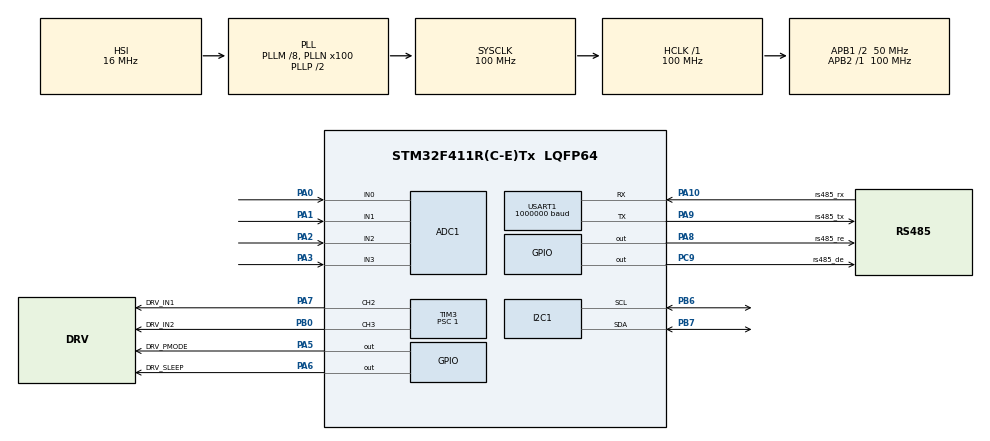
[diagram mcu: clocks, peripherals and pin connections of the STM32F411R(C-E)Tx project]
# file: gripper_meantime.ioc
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ADC1.Channel-0\#ChannelRegularConversion=ADC_CHANNEL_0
ADC1.Channel-1\#ChannelRegularConversion=ADC_CHANNEL_1
ADC1.Channel-2\#ChannelRegularConversion=ADC_CHANNEL_2
ADC1.Channel-3\#ChannelRegularConversion=ADC_CHANNEL_3
ADC1.Channel-4\#ChannelRegularConversion=ADC_CHANNEL_TEMPSENSOR
ADC1.ContinuousConvMode=ENABLE
ADC1.DMAContinuousRequests=DISABLE
ADC1.NbrOfConversion=5
ADC1.NbrOfConversionFlag=1
ADC1.Rank-0\#ChannelRegularConversion=1
ADC1.Rank-1\#ChannelRegularConversion=2
ADC1.Rank-2\#ChannelRegularConversion=3
ADC1.Rank-3\#ChannelRegularConversion=4
ADC1.Rank-4\#ChannelRegularConversion=5
ADC1.SamplingTime-0\#ChannelRegularConversion=ADC_SAMPLETIME_3CYCLES
ADC1.SamplingTime-1\#ChannelRegularConversion=ADC_SAMPLETIME_3CYCLES
ADC1.SamplingTime-2\#ChannelRegularConversion=ADC_SAMPLETIME_3CYCLES
ADC1.SamplingTime-3\#ChannelRegularConversion=ADC_SAMPLETIME_3CYCLES
ADC1.SamplingTime-4\#ChannelRegularConversion=ADC_SAMPLETIME_3CYCLES
ADC1.ScanConvMode=ENABLE
ADC1.master=1
Dma.ADC1.0.Direction=DMA_PERIPH_TO_MEMORY
Dma.ADC1.0.FIFOMode=DMA_FIFOMODE_DISABLE
Dma.ADC1.0.Instance=DMA2_Stream0
Dma.ADC1.0.MemDataAlignment=DMA_MDATAALIGN_WORD
Dma.ADC1.0.MemInc=DMA_MINC_ENABLE
Dma.ADC1.0.Mode=DMA_CIRCULAR
Dma.ADC1.0.PeriphDataAlignment=DMA_PDATAALIGN_WORD
Dma.ADC1.0.PeriphInc=DMA_PINC_DISABLE
Dma.ADC1.0.Priority=DMA_PRIORITY_LOW
Dma.Request0=ADC1
Dma.Request1=USART1_RX
Dma.USART1_RX.1.Direction=DMA_PERIPH_TO_MEMORY
Dma.USART1_RX.1.FIFOMode=DMA_FIFOMODE_DISABLE
Dma.USART1_RX.1.Instance=DMA2_Stream2
Dma.USART1_RX.1.MemDataAlignment=DMA_MDATAALIGN_BYTE
Dma.USART1_RX.1.MemInc=DMA_MINC_ENABLE
Dma.USART1_RX.1.Mode=DMA_NORMAL
Dma.USART1_RX.1.PeriphDataAlignment=DMA_PDATAALIGN_BYTE
Dma.USART1_RX.1.PeriphInc=DMA_PINC_DISABLE
Dma.USART1_RX.1.Priority=DMA_PRIORITY_LOW
Mcu.Family=STM32F4
Mcu.Name=STM32F411R(C-E)Tx
Mcu.Package=LQFP64
NVIC.DMA2_Stream0_IRQn=true\:1\:0\:true\:false\:true\:false\:true\:true
NVIC.DMA2_Stream2_IRQn=true\:0\:0\:false\:false\:true\:false\:true\:true
NVIC.PriorityGroup=NVIC_PRIORITYGROUP_4
PA0-WKUP.Signal=ADCx_IN0
PA1.Signal=ADCx_IN1
PA10.GPIO_Label=rs485_rx
PA10.Mode=Asynchronous
PA10.Signal=USART1_RX
PA2.Signal=ADCx_IN2
PA3.Signal=ADCx_IN3
PA5.GPIO_Label=DRV_PMODE
PA5.Signal=GPIO_Output
PA6.GPIO_Label=DRV_SLEEP
PA6.Signal=GPIO_Output
PA7.GPIO_Label=DRV_IN1
PA7.Signal=S_TIM3_CH2
PA8.GPIO_Label=rs485_re
PA8.Signal=GPIO_Output
PA9.GPIO_Label=rs485_tx
PA9.Mode=Asynchronous
PA9.Signal=USART1_TX
PB0.GPIO_Label=DRV_IN2
PB0.Signal=S_TIM3_CH3
PB6.Mode=I2C
PB6.Signal=I2C1_SCL
PB7.Mode=I2C
PB7.Signal=I2C1_SDA
PC9.GPIO_Label=rs485_de
PC9.Signal=GPIO_Output
ProjectManager.HeapSize=0x200
ProjectManager.StackSize=0x400
ProjectManager.TargetToolchain=STM32CubeIDE
RCC.48MHZClocksFreq_Value=50000000
RCC.AHBFreq_Value=100000000
RCC.APB1CLKDivider=RCC_HCLK_DIV2
RCC.APB1Freq_Value=50000000
RCC.APB1TimFreq_Value=100000000
RCC.APB2Freq_Value=100000000
RCC.APB2TimFreq_Value=100000000
RCC.CortexFreq_Value=100000000
RCC.HCLKFreq_Value=100000000
RCC.HSE_VALUE=25000000
RCC.HSI_VALUE=16000000
RCC.LSE_VALUE=32768
RCC.PLLM=8
RCC.PLLN=100
RCC.SYSCLKFreq_VALUE=100000000
RCC.SYSCLKSource=RCC_SYSCLKSOURCE_PLLCLK
RCC.VCOOutputFreq_Value=200000000
SH.ADCx_IN0.0=ADC1_IN0,IN0
SH.ADCx_IN1.0=ADC1_IN1,IN1
SH.ADCx_IN2.0=ADC1_IN2,IN2
SH.ADCx_IN3.0=ADC1_IN3,IN3
SH.S_TIM3_CH2.0=TIM3_CH2,PWM Generation2 CH2
SH.S_TIM3_CH3.0=TIM3_CH3,PWM Generation3 CH3
TIM1.AutoReloadPreload=TIM_AUTORELOAD_PRELOAD_ENABLE
TIM1.Period=2499
TIM1.Prescaler=1
TIM3.AutoReloadPreload=TIM_AUTORELOAD_PRELOAD_ENABLE
TIM3.Channel-PWM\ Generation2\ CH2=TIM_CHANNEL_2
TIM3.Channel-PWM\ Generation3\ CH3=TIM_CHANNEL_3
TIM3.Period=2499
TIM3.Prescaler=1
USART1.BaudRate=1000000
USART1.VirtualMode=VM_ASYNC
VP_ADC1_TempSens_Input.Mode=IN-TempSens
VP_TIM1_VS_ClockSourceINT.Mode=Internal
board=custom

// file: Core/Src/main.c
/* USER CODE BEGIN Header */
/**
  ******************************************************************************
  * @file           : main.c
  * @brief          : Main program body
  ******************************************************************************
  * @attention
  *
  * Copyright (c) 2023 STMicroelectronics.
  * All rights reserved.
  *
  * This software is licensed under terms that can be found in the LICENSE file
  * in the root directory of this software component.
  * If no LICENSE file comes with this software, it is provided AS-IS.
  *
  ******************************************************************************
  */
/* USER CODE END Header */
#include "main.h"
#include "adc.h"
#include "dma.h"
#include "i2c.h"
#include "tim.h"
#include "usart.h"
#include "gpio.h"

void SystemClock_Config(void);

int main(void)
{

  /* MCU Configuration--------------------------------------------------------*/

  /* Reset of all peripherals, Initializes the Flash interface and the Systick. */
  HAL_Init();

  /* Configure the system clock */
  SystemClock_Config();

  /* Initialize all configured peripherals */
  MX_GPIO_Init();
  MX_DMA_Init();
  MX_I2C1_Init();
  MX_ADC1_Init();
  MX_TIM1_Init();
  MX_TIM3_Init();
  MX_USART1_UART_Init();
  /* USER CODE BEGIN 2 */
  loop_init();

  /* USER CODE END 2 */

  /* Infinite loop */
  while (1)
  {

    /* USER CODE BEGIN 3 */

  loop();
  }

  /* USER CODE END 3 */
}

void SystemClock_Config(void)
{
  RCC_OscInitTypeDef RCC_OscInitStruct = {0};
  RCC_ClkInitTypeDef RCC_ClkInitStruct = {0};

  /** Configure the main internal regulator output voltage
  */
  __HAL_RCC_PWR_CLK_ENABLE();
  __HAL_PWR_VOLTAGESCALING_CONFIG(PWR_REGULATOR_VOLTAGE_SCALE1);

  /** Initializes the RCC Oscillators according to the specified parameters
  * in the RCC_OscInitTypeDef structure.
  */
  RCC_OscInitStruct.OscillatorType = RCC_OSCILLATORTYPE_HSI;
  RCC_OscInitStruct.HSIState = RCC_HSI_ON;
  RCC_OscInitStruct.HSICalibrationValue = RCC_HSICALIBRATION_DEFAULT;
  RCC_OscInitStruct.PLL.PLLState = RCC_PLL_ON;
  RCC_OscInitStruct.PLL.PLLSource = RCC_PLLSOURCE_HSI;
  RCC_OscInitStruct.PLL.PLLM = 8;
  RCC_OscInitStruct.PLL.PLLN = 100;
  RCC_OscInitStruct.PLL.PLLP = RCC_PLLP_DIV2;
  RCC_OscInitStruct.PLL.PLLQ = 4;
  if (HAL_RCC_OscConfig(&RCC_OscInitStruct) != HAL_OK)
  {
    Error_Handler();
  }

  /** Initializes the CPU, AHB and APB buses clocks
  */
  RCC_ClkInitStruct.ClockType = RCC_CLOCKTYPE_HCLK|RCC_CLOCKTYPE_SYSCLK
                              |RCC_CLOCKTYPE_PCLK1|RCC_CLOCKTYPE_PCLK2;
  RCC_ClkInitStruct.SYSCLKSource = RCC_SYSCLKSOURCE_PLLCLK;
  RCC_ClkInitStruct.AHBCLKDivider = RCC_SYSCLK_DIV1;
  RCC_ClkInitStruct.APB1CLKDivider = RCC_HCLK_DIV2;
  RCC_ClkInitStruct.APB2CLKDivider = RCC_HCLK_DIV1;

  if (HAL_RCC_ClockConfig(&RCC_ClkInitStruct, FLASH_LATENCY_3) != HAL_OK)
  {
    Error_Handler();
  }
}

void Error_Handler(void)
{
  __disable_irq();
  while (1)
  {
  }
}
